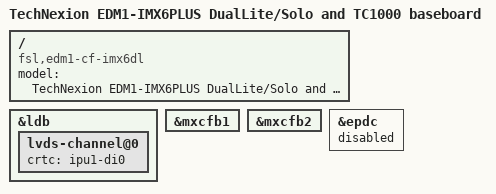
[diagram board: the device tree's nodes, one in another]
/*
 * Copyright 2016 Technexion Ltd.
 *
 * Author: Alvin Chen <alvin.chen@technexion.com>
 *
 * The code contained herein is licensed under the GNU General Public
 * License. You may obtain a copy of the GNU General Public License
 * Version 2 or later at the following locations:
 *
 * http://www.opensource.org/licenses/gpl-license.html
 * http://www.gnu.org/copyleft/gpl.html
 */

/dts-v1/;

#include <dt-bindings/interrupt-controller/irq.h>
#include "imx6dl.dtsi"
#include "imx6qdl-edm1-cf-pmic-lcd15.dtsi"
#include "baseboard_edm1_tc1000.dtsi"

/ {
	model = "TechNexion EDM1-IMX6PLUS DualLite/Solo and TC1000 baseboard";
	compatible = "fsl,edm1-cf-imx6dl", "fsl,imx6dl";
};

&ldb {
	lvds-channel@0 {
		crtc = "ipu1-di0";
	};
};

&mxcfb1 {
	status = "okay";
};

&mxcfb2 {
	status = "okay";
};

#if 0
&mxcfb3 {
	status = "okay";
};

&mxcfb4 {
	status = "okay";
};
#endif

&epdc {
	status = "disabled";
};
